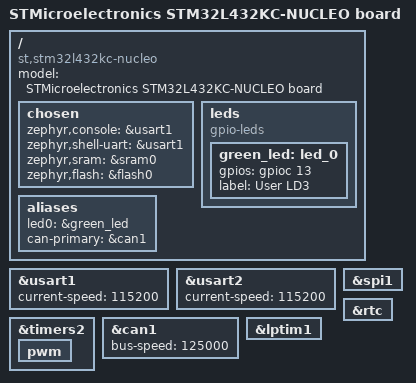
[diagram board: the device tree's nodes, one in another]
/*
 * Copyright (c) 2017 Linaro Limited
 *
 * SPDX-License-Identifier: Apache-2.0
 */

/dts-v1/;
#include <st/l4/stm32l432Xc.dtsi>

/ {
	model = "STMicroelectronics STM32L432KC-NUCLEO board";
	compatible = "st,stm32l432kc-nucleo", "st,stm32l432";

	chosen {
		zephyr,console = &usart1;
		zephyr,shell-uart = &usart1;
		zephyr,sram = &sram0;
		zephyr,flash = &flash0;
	};

	leds {
		compatible = "gpio-leds";
		green_led: led_0 {
			gpios = <&gpioc 13 GPIO_ACTIVE_HIGH>;
			label = "User LD3";
		};
	};

	aliases {
		led0 = &green_led;
		can-primary = &can1;
	};
};

&usart1 {
	current-speed = <115200>;
	status = "okay";
};

&usart2 {
	current-speed = <115200>;
	status = "okay";
};

&spi1 {
	status = "okay";
};

&timers2 {
	status = "okay";

	pwm {
		status = "okay";
	};
};

&can1 {
	bus-speed = <125000>;
	status = "okay";
};

&rtc {
	status = "okay";
};

&lptim1 {
	status = "okay";
};
